# LPC800 register map
File version: 0.2
CPU: CM0 r0p0, little endian, no MPU, no FPU, 2 interrupt priority bits
Registers are 32-bit, read-write, reset 0x0 unless marked. A register's access mark holds for its fields unless they carry their own. Offsets are from the block's base; [hi:lo] are bit positions; {n}, {i} and the like mark numbered series; 'fields as' and 'values as' point back to an identical list.

## SYSCON — System configuration (SYSCON)
Base 0x40048000
0x00 SYSMEMREMAP reset 0x2 — System memory remap
  [1:0] MAP — System memory remap. Value 0x3 is reserved.
    0=BOOT_LOADER_MODE_IN (Boot Loader Mode. Interrupt vectors are re-mapped to Boot ROM.); 1=USER_RAM_MODE_INTER (User RAM Mode. Interrupt vectors are re-mapped to Static RAM.); 2=USER_FLASH_MODE_INT (User Flash Mode. Interrupt vectors are not re-mapped and reside in Flash.)
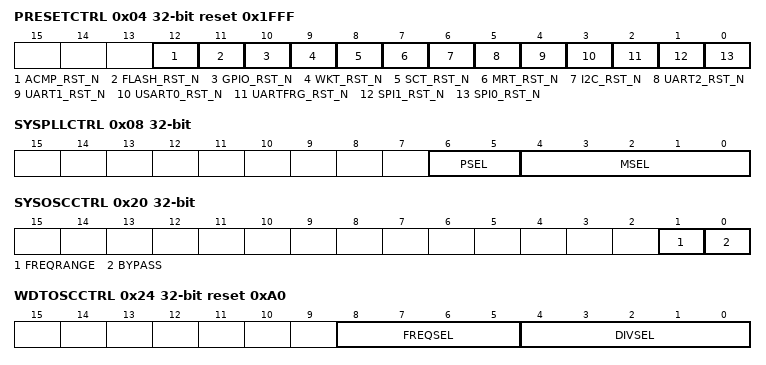
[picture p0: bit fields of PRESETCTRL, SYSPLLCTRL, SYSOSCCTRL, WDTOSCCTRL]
0x04 PRESETCTRL reset 0x1FFF — Peripheral reset control
  [12] ACMP_RST_N — Analog comparator reset control
    0=ASSERT_THE_ANALOG_CO (Assert the analog comparator reset.); 1=CLEAR_THE_ANALOG_COM (Clear the analog comparator controller reset.)
  [11] FLASH_RST_N — Flash controller reset control
    0=ASSERT_THE_FLASH_CON (Assert the flash controller reset.); 1=CLEAR_THE_FLASH_CONT (Clear the flash controller reset.)
  [10] GPIO_RST_N — GPIO and GPIO pin interrupt reset control
    0=ASSERT_THE_GPIO_RESE (Assert the GPIO reset.); 1=CLEAR_THE_GPIO_RESET
  [9] WKT_RST_N — Self wake-up timer (WKT) reset control
    0=ASSERT_THE_WKT_RESET; 1=CLEAR_THE_WKT_RESET_
  [8] SCT_RST_N — SCT reset control
    0=ASSERT_THE_SCT_RESET; 1=CLEAR_THE_SCT_RESET_
  [7] MRT_RST_N — Multi-rate timer (MRT) reset control
    0=ASSERT_THE_MRT_RESET; 1=CLEAR_THE_MRT_RESET_
  [6] I2C_RST_N — I2C reset control
    0=ASSERT_THE_I2C_RESET; 1=CLEAR_THE_I2C_RESET_
  [5] UART2_RST_N — UART2 reset control
    0=ASSERT_THE_UART2_RES (Assert the UART2 reset.); 1=CLEAR_THE_UART2_RESE (Clear the UART2 reset.)
  [4] UART1_RST_N — U1ART1 reset control
    0=ASSERT_THE_UART_RESE (Assert the UART reset.); 1=CLEAR_THE_UART1_RESE (Clear the UART1 reset.)
  [3] USART0_RST_N — USART0 reset control
    0=ASSERT_THE_USART0_RE (Assert the USART0 reset.); 1=CLEAR_THE_USART0_RES (Clear the USART0 reset.)
  [2] UARTFRG_RST_N — UART fractional baud rate generator (UARTFRG) reset control
    0=ASSERT_THE_UARTFRG_R (Assert the UARTFRG reset.); 1=CLEAR_THE_UARTFRG_RE (Clear the UARTFRG reset.)
  [1] SPI1_RST_N — SPI1 reset control
    0=ASSERT_THE_SPI1_RESE (Assert the SPI1 reset.); 1=CLEAR_THE_SPI1_RESET
  [0] SPI0_RST_N — SPI0 reset control
    0=ASSERT_THE_SPI0_RESE (Assert the SPI0 reset.); 1=CLEAR_THE_SPI0_RESET
0x08 SYSPLLCTRL — System PLL control
  [6:5] PSEL — Post divider ratio P. The division ratio is 2 x P.
    0=P_EQ_1 (P = 1); 1=P_EQ_2 (P = 2); 2=P_EQ_4 (P = 4); 3=P_EQ_8 (P = 8)
  [4:0] MSEL — Feedback divider value. The division value M is the programmed MSEL value + 1. 00000: Division ratio M = 1 to 11111: Division ratio M = 32
0x0C SYSPLLSTAT ro — System PLL status
  [0] LOCK — PLL lock status
    0=PLL_NOT_LOCKED; 1=PLL_LOCKED
0x20 SYSOSCCTRL — System oscillator control
  [1] FREQRANGE — Determines frequency range for Low-power oscillator.
    0=1__20_MHZ_FREQUENCY (1 - 20 MHz frequency range.); 1=15__25_MHZ_FREQUENC (15 - 25 MHz frequency range)
  [0] BYPASS — Bypass system oscillator
    0=DISABLED_OSCILLATOR (Disabled. Oscillator is not bypassed.); 1=ENABLED_PLL_INPUT_ (Enabled. PLL input (sys_osc_clk) is fed directly from the XTALIN pin bypassing the oscillator. Use this mode when using an external clock source instead of the crystal oscillator.)
0x24 WDTOSCCTRL reset 0xA0 — Watchdog oscillator control
  [8:5] FREQSEL — Select watchdog oscillator analog output frequency (Fclkana).
    1=0_6_MHZ; 2=1_05_MHZ; 3=1_4_MHZ; 4=1_75_MHZ; 5=2_1_MHZ; 6=2_4_MHZ; 7=2_7_MHZ; 8=3_0_MHZ; 9=3_25_MHZ; 10=3_5_MHZ; 11=3_75_MHZ; 12=4_0_MHZ; 13=4_2_MHZ; 14=4_4_MHZ; 15=4_6_MHZ
  [4:0] DIVSEL — Select divider for Fclkana. wdt_osc_clk = Fclkana/ (2 x (1 + DIVSEL)) 00000: 2 x (1 + DIVSEL) = 2 00001: 2 x (1 + DIVSEL) = 4 to 11111: 2 x (1 + DIVSEL) = 64
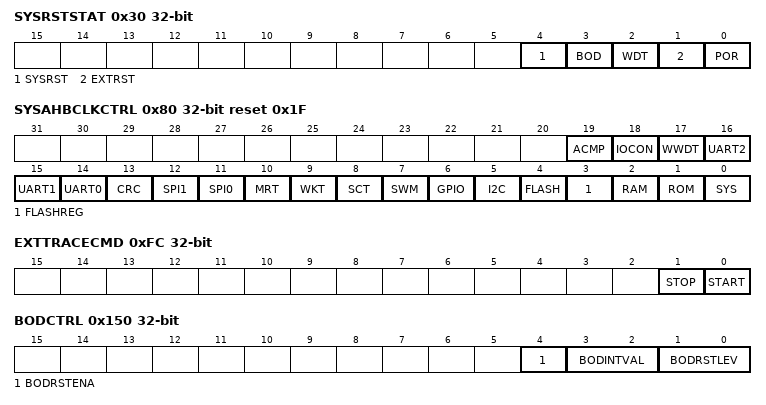
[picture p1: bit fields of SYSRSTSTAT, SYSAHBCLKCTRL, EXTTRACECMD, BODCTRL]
0x30 SYSRSTSTAT — System reset status register
  [4] SYSRST — Status of the software system reset
    0=NO_SYSTEM_RESET_DETE (No System reset detected); 1=SYSTEM_RESET_DETECTE (System reset detected. Writing a one clears this reset.)
  [3] BOD — Status of the Brown-out detect reset
    0=NO_BOD_RESET_DETECTE (No BOD reset detected); 1=BOD_RESET_DETECTED_ (BOD reset detected. Writing a one clears this reset.)
  [2] WDT — Status of the Watchdog reset
    0=NO_WDT_RESET_DETECTE (No WDT reset detected); 1=WDT_RESET_DETECTED_ (WDT reset detected. Writing a one clears this reset.)
  [1] EXTRST — Status of the external RESET pin. External reset status.
    0=NO_RESET_EVENT_DETEC (No reset event detected.); 1=RESET_DETECTED_WRIT (Reset detected. Writing a one clears this reset.)
  [0] POR — POR reset status
    0=NO_POR_DETECTED; 1=POR_DETECTED_WRITIN (POR detected. Writing a one clears this reset.)
0x40 SYSPLLCLKSEL — System PLL clock source select
  [1:0] SEL — System PLL clock source
    0=IRC; 1=CRYSTAL_OSCILLATOR_ (Crystal Oscillator (SYSOSC)); 3=CLKIN_EXTERNAL_CLOC (CLKIN. External clock input.)
0x44 SYSPLLCLKUEN — System PLL clock source update enable
  [0] ENA — Enable system PLL clock source update
    0=NO_CHANGE; 1=UPDATE_CLOCK_SOURCE
0x70 MAINCLKSEL — Main clock source select
  [1:0] SEL — Clock source for main clock
    0=IRC_OSCILLATOR; 1=PLL_INPUT; 2=WATCHDOG_OSCILLATOR; 3=PLL_OUTPUT
0x74 MAINCLKUEN — Main clock source update enable
  [0] ENA — Enable main clock source update
    0=NO_CHANGE; 1=UPDATE_CLOCK_SOURCE
0x78 SYSAHBCLKDIV reset not defined — System clock divider
  [7:0] DIV — System AHB clock divider values 0: System clock disabled. 1: Divide by 1. to 255: Divide by 255.
0x80 SYSAHBCLKCTRL reset 0x1F — System clock control
  [19] ACMP — Enables clock to analog comparator.
    0=DISABLE; 1=ENABLE
  [18] IOCON — Enables clock for IOCON block.
    0=DISABLE; 1=ENABLE
  [17] WWDT — Enables clock for WWDT.
    0=DISABLE; 1=ENABLE
  [16] UART2 — Enables clock for UART2.
    0=DISABLE; 1=ENABLE
  [15] UART1 — Enables clock for UART1.
    0=DISABLE; 1=ENABLE
  [14] UART0 — Enables clock for UART0.
    0=DISABLE; 1=ENABLE
  [13] CRC — Enables clock for CRC.
    0=DISABLE; 1=ENABLE
  [12] SPI1 — Enables clock for SPI1.
    0=DISABLE; 1=ENABLE
  [11] SPI0 — Enables clock for SPI0.
    0=DISABLE; 1=ENABLE
  [10] MRT — Enables clock for multi-rate timer.
    0=DISABLE; 1=ENABLE
  [9] WKT — Enables clock for self wake-up timer.
    0=DISABLE; 1=ENABLE
  [8] SCT — Enables clock for state configurable timer.
    0=DISABLE; 1=ENABLE
  [7] SWM — Enables clock for switch matrix.
    0=DISABLE; 1=ENABLE
  [6] GPIO — Enables clock for GPIO port registers and GPIO pin interrupt registers.
    0=DISABLE; 1=ENABLE
  [5] I2C — Enables clock for I2C.
    0=DISABLE; 1=ENABLE
  [4] FLASH — Enables clock for flash.
    0=DISABLE; 1=ENABLE
  [3] FLASHREG — Enables clock for flash register interface.
    0=DISABLE; 1=ENABLE
  [2] RAM — Enables clock for SRAM.
    0=DISABLE; 1=ENABLE
  [1] ROM — Enables clock for ROM.
    0=DISABLE; 1=ENABLE
  [0] SYS — Enables the clock for the AHB, the APB bridge, the Cortex-M0+ core clocks, SYSCON, and the PMU. This bit is read only and always reads as 1.
    1=ENABLE
0x94 UARTCLKDIV — UART clock divider
  [7:0] DIV — UART clock divider values. 0: Clock disabled. 1: Divide by 1. to 255: Divide by 255.
0xE0 CLKOUTSEL — CLKOUT clock source select
  [1:0] SEL — CLKOUT clock source
    0=IRC_OSCILLATOR; 1=CRYSTAL_OSCILLATOR_ (Crystal oscillator (SYSOSC)); 2=WATCHDOG_OSCILLATOR; 3=MAIN_CLOCK
0xE4 CLKOUTUEN — CLKOUT clock source update enable
  [0] ENA — Enable CLKOUT clock source update
    0=NO_CHANGE; 1=UPDATE_CLOCK_SOURCE
0xE8 CLKOUTDIV — CLKOUT clock divider
  [7:0] DIV — CLKOUT clock divider values 0: Disable CLKOUT clock divider. 1: Divide by 1. to 255: Divide by 255.
0xF0 UARTFRGDIV — UART fractional generator divider value
  [7:0] DIV — Denominator of the fractional divider. DIV is equal to the programmed value +1. Always set to 0xFF to use with the fractional baud rate generator.
0xF4 UARTFRGMULT — UART fractional generator multiplier value
  [7:0] MULT — Numerator of the fractional divider. MULT is equal to the programmed value.
0xFC EXTTRACECMD — External trace buffer command register
  [1] STOP — Trace stop command
  [0] START — Trace start command
0x100 PIOPORCAP0 ro reset not defined — POR captured PIO status 0
  [17:0] PIOSTAT — State of PIO0_17 through PIO0_0 at power-on reset
0x134 IOCONCLKDIV6 — Peripheral clock 6 to the IOCON block for programmable glitch filter
  [7:0] DIV — IOCON glitch filter clock divider values 0: Disable IOCONFILTR_PCLK. 1: Divide by 1. to 255: Divide by 255.
0x138 IOCONCLKDIV5 — Peripheral clock 5 to the IOCON block for programmable glitch filter
  fields as IOCONCLKDIV6
0x13C IOCONCLKDIV4 — Peripheral clock 4 to the IOCON block for programmable glitch filter
  fields as IOCONCLKDIV6
0x140 IOCONCLKDIV3 — Peripheral clock 3 to the IOCON block for programmable glitch filter
  fields as IOCONCLKDIV6
0x144 IOCONCLKDIV2 — Peripheral clock 2 to the IOCON block for programmable glitch filter
  fields as IOCONCLKDIV6
0x148 IOCONCLKDIV1 — Peripheral clock 1 to the IOCON block for programmable glitch filter
  fields as IOCONCLKDIV6
0x14C IOCONCLKDIV0 — Peripheral clock 0 to the IOCON block for programmable glitch filter
  fields as IOCONCLKDIV6
0x150 BODCTRL — Brown-Out Detect
  [4] BODRSTENA — BOD reset enable
    0=DISABLE_RESET_FUNCTI (Disable reset function.); 1=ENABLE_RESET_FUNCTIO (Enable reset function.)
  [3:2] BODINTVAL — BOD interrupt level
    0=LEVEL_0_THE_INTERRU (Level 0: The interrupt assertion threshold voltage is ; the interrupt de-assertion threshold voltage is); 1=LEVEL_1THE_INTERRUP (Level 1:The interrupt assertion threshold voltage is ; the interrupt de-assertion threshold voltage is .); 2=LEVEL_2_THE_INTERRU (Level 2: The interrupt assertion threshold voltage is ; the interrupt de-assertion threshold voltage is .); 3=LEVEL_3_THE_INTERRU (Level 3: The interrupt assertion threshold voltage is ; the interrupt de-assertion threshold voltage is .)
  [1:0] BODRSTLEV — BOD reset level
    0=LEVEL_0_THE_RESET_A (Level 0: The reset assertion threshold voltage is ; the reset de-assertion threshold voltage is .); 1=LEVEL_1_THE_RESET_A (Level 1: The reset assertion threshold voltage is ; the reset de-assertion threshold voltage is .); 2=LEVEL_2_THE_RESET_A (Level 2: The reset assertion threshold voltage is ; the reset de-assertion threshold voltage is .); 3=LEVEL_3_THE_RESET_A (Level 3: The reset assertion threshold voltage is ; the reset de-assertion threshold voltage is.)
0x154 SYSTCKCAL — System tick counter calibration
  [25:0] CAL — System tick timer calibration value
0x170 IRQLATENCY reset 0x10 — IQR delay. Allows trade-off between interrupt latency and determinism.
  [7:0] LATENCY — 8-bit latency value
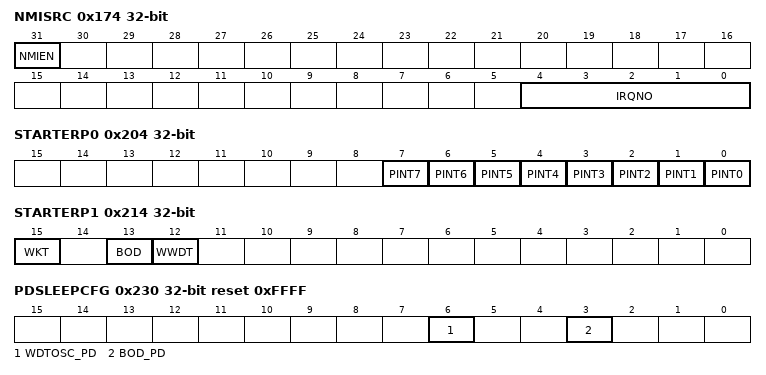
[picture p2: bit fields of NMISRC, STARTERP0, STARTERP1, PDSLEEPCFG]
0x174 NMISRC — NMI Source Control
  [31] NMIEN — Write a 1 to this bit to enable the Non-Maskable Interrupt (NMI) source selected by bits 4:0.
  [4:0] IRQNO — The IRQ number of the interrupt that acts as the Non-Maskable Interrupt (NMI) if bit 31 is 1. See Table 58 for the list of interrupt sources and their IRQ numbers.
{0x178+4i} PINTSEL{i} (i=0..7) — GPIO Pin Interrupt Select register 0
  [5:0] INTPIN — Pin number select for pin interrupt or pattern match engine input. (PIO0_0 to PIO0_17 correspond to numbers 0 to 17).
0x204 STARTERP0 — Start logic 0 pin wake-up enable register
  [all] fields
    0=DISABLED; 1=ENABLED
  [n] PINT{n} (n=0..7) — GPIO pin interrupt {n} wake-up
0x214 STARTERP1 — Start logic 1 interrupt wake-up enable register
  [all] fields
    0=DISABLED; 1=ENABLED
  [15] WKT — Self wake-up timer interrupt wake-up
  [13] BOD — BOD interrupt wake-up
  [12] WWDT — WWDT interrupt wake-up
0x230 PDSLEEPCFG reset 0xFFFF — Power-down states in deep-sleep mode
  [6] WDTOSC_PD — Watchdog oscillator power-down control for Deep-sleep and Power-down mode. Changing this bit to powered-down has no effect when the LOCK bit in the WWDT MOD register is set. In this case, the watchdog oscillator is always running.
    0=POWERED; 1=POWERED_DOWN
  [3] BOD_PD — BOD power-down control for Deep-sleep and Power-down mode
    0=POWERED; 1=POWERED_DOWN
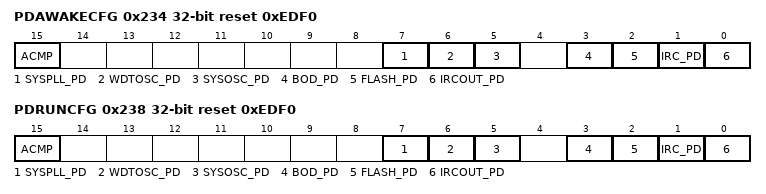
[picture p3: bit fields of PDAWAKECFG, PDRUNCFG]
0x234 PDAWAKECFG reset 0xEDF0 — Power-down states for wake-up from deep-sleep
  [all] fields
    0=POWERED; 1=POWERED_DOWN
  [15] ACMP — Analog comparator wake-up configuration
  [7] SYSPLL_PD — System PLL wake-up configuration
  [6] WDTOSC_PD — Watchdog oscillator wake-up configuration. Changing this bit to powered-down has no effect when the LOCK bit in the WWDT MOD register is set. In this case, the watchdog oscillator is always running.
  [5] SYSOSC_PD — Crystal oscillator wake-up configuration
  [3] BOD_PD — BOD wake-up configuration
  [2] FLASH_PD — Flash wake-up configuration
  [1] IRC_PD — IRC oscillator power-down wake-up configuration
  [0] IRCOUT_PD — IRC oscillator output wake-up configuration
0x238 PDRUNCFG reset 0xEDF0 — Power configuration register
  [all] fields
    0=POWERED; 1=POWERED_DOWN
  [15] ACMP — Analog comparator power down
  [7] SYSPLL_PD — System PLL power down
  [6] WDTOSC_PD — Watchdog oscillator power down. Changing this bit to powered-down has no effect when the LOCK bit in the WWDT MOD register is set. In this case, the watchdog oscillator is always running.
  [5] SYSOSC_PD — Crystal oscillator power down
  [3] BOD_PD — BOD power down
  [2] FLASH_PD — Flash power down
  [1] IRC_PD — IRC oscillator power down
  [0] IRCOUT_PD — IRC oscillator output power
0x3F4 DEVICE_ID ro reset not defined
  [31:0] DEVICEID
